AUTOSAR XML (schema 4-2-2)
package /ComponentTypes
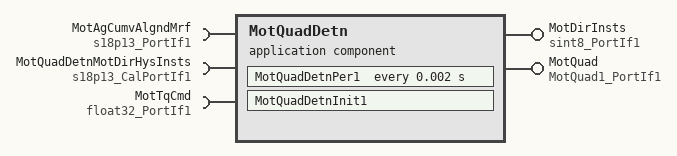
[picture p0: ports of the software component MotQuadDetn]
  application sw component type MotQuadDetn
    provide port MotDirInsts: nonqueued-sender-com-spec{data-element=Val, init-value=1}, provided-interface=sint8_PortIf1
    provide port MotQuad: nonqueued-sender-com-spec{data-element=Val, init-value=1}, provided-interface=MotQuad1_PortIf1
    require port MotAgCumvAlgndMrf: nonqueued-receiver-com-spec{data-element=Val, filter=data-filter-type=ALWAYS, init-value=0}, required-interface=s18p13_PortIf1
    require port MotQuadDetnMotDirHysInsts: parameter-require-com-spec{init-value=20480, parameter=Val}, required-interface=s18p13_CalPortIf1
    require port MotTqCmd: nonqueued-receiver-com-spec{data-element=Val, filter=data-filter-type=ALWAYS, init-value=0}, required-interface=float32_PortIf1
    behavior MotQuadDetn_InternalBehavior
      ar-typed-per-instance-memorys:
        5 x data, all with sw-calibration-access=READ-ONLY:
          dMotQuadDetnMotAgCumvDelta: type=s18p13
          dMotQuadDetnTqCmdSign: type=sint8
          MotAgCumvPrev: type=s18p13
          MotDirInstsPrev: type=sint8
          MotTqCmdSignPrev: type=sint8
      init event MotQuadDetn_InitEvent: start-on-event=MotQuadDetnInit1
      timing event TMT_MotQuadDetnPer1: start-on-event=MotQuadDetnPer1, period=0.002
      port-api-options:
        enable-take-address=false, error-handling=NO-TRANSFORMER-ERROR-HANDLING, indirect-api=false, port=MotAgCumvAlgndMrf
        enable-take-address=false, error-handling=NO-TRANSFORMER-ERROR-HANDLING, indirect-api=false, port=MotDirInsts
        enable-take-address=false, error-handling=NO-TRANSFORMER-ERROR-HANDLING, indirect-api=false, port=MotQuad
      runnable MotQuadDetnInit1
      runnable MotQuadDetnPer1
        data-receive-point-by-arguments:
          access REC_MotAgCumvAlgndMrf_Val_1: accessed-variable=MotAgCumvAlgndMrf.Val
          access REC_MotTqCmd_Val: accessed-variable=MotTqCmd.Val
        data-send-points:
          access SEND_MotDirInsts_Val_1: accessed-variable=MotDirInsts.Val
          access SEND_MotQuad_Val_1: accessed-variable=MotQuad.Val
  swc implementation MotQuadDetn_Implementation: behavior=MotQuadDetn_InternalBehavior
    code-descriptors:
      code Default: artifact-descriptors=autosar-engineering-object={short-label=Default, category=SWSRC}
